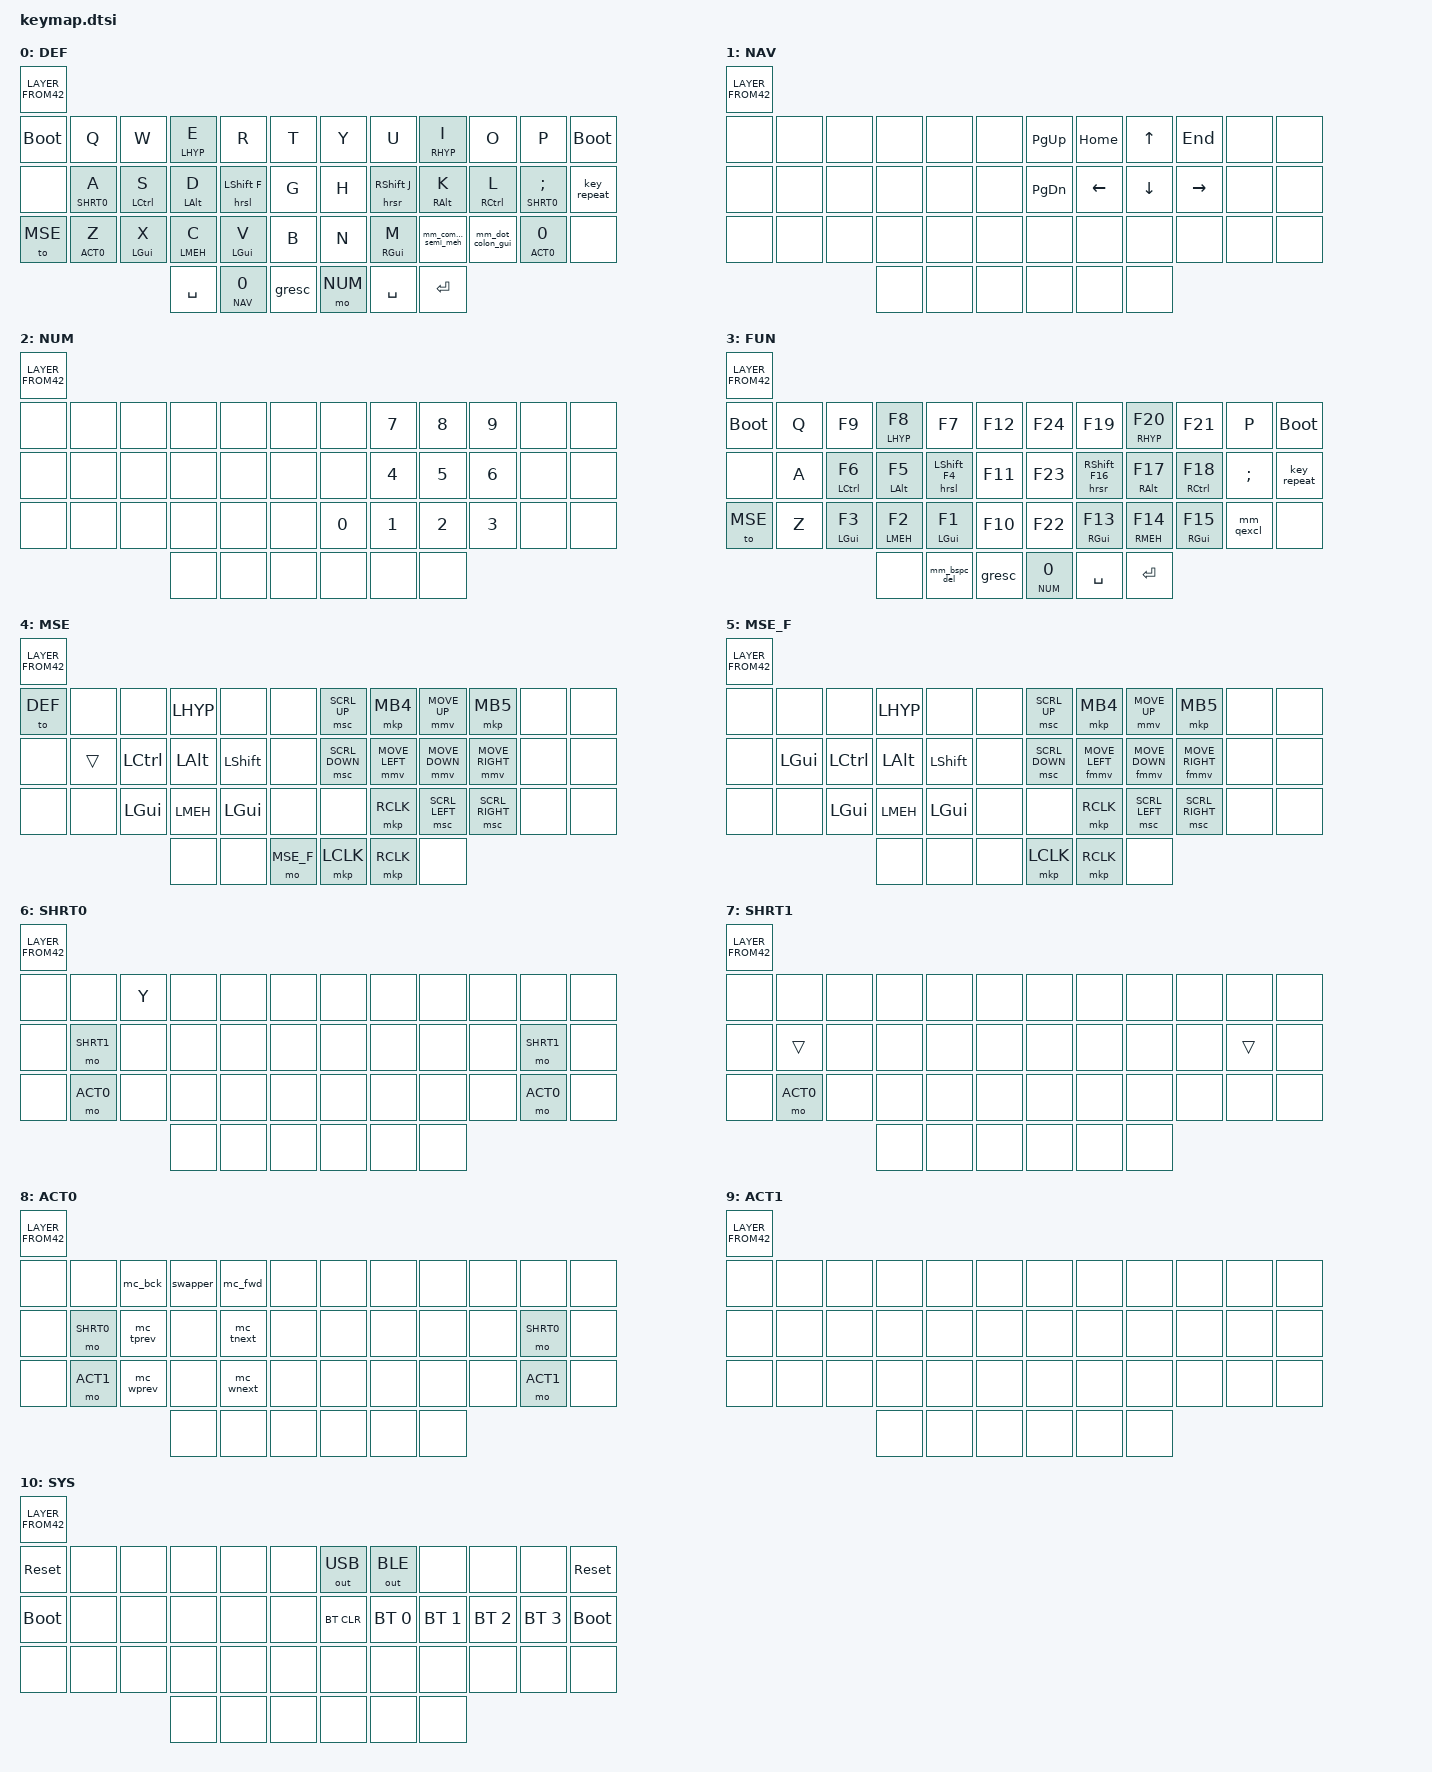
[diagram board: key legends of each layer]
/*
 * Copyright (c) 2020 The ZMK Contributors
 *
 * SPDX-License-Identifier: MIT
 */

#include <dt-bindings/zmk/bt.h>
#include <dt-bindings/zmk/keys.h>
// #include <dt-bindings/zmk/mouse.h>
#include <dt-bindings/zmk/outputs.h>

#ifndef KEYMAP_DRAWER
#include "include/keys_de.h"
#endif

#define DEF    0
#define NAV    1
#define NUM    2
#define FUN    3
#define MSE    4
#define MSE_F  5
#define SHRT0  6
#define SHRT1  7
#define ACT0   8
#define ACT1   9


#include "include/keypos.h"
#include "keycodes.dtsi"
#include "behaviors.dtsi"
#include "combos.dtsi"
#include "macros.dtsi"
#include "mouse.dtsi"

/ {
    conditional_layers {
        compatible = "zmk,conditional-layers";

        tri_layer  {
            if-layers = <NAV NUM>;
            then-layer = <FUN>;
        };
    };

    keymap {
        compatible = "zmk,keymap";

        default {
            display-name = "DEF";
            bindings = <LAYER_FROM42( \
// ┌───────────────────┬───────────────────┬───────────────────┬───────────────────┬───────────────────┬───────────────────╥───────────────────┬───────────────────┬───────────────────┬───────────────────┬───────────────────┬───────────────────┐
    &bootloader,        &kp Q,              &kp W,              &hrml LHYP E,       &kp R,              &kp T,              &kp Y,              &kp U,              &hrmr RHYP I,              &kp O,              &kp P,       &bootloader,       \
    &none,              &ltb SHRT0 A,       &hrml LCTL S,       &hrml LALT D,       &hrsl LSHFT F,      &kp G,              &kp H,              &hrsr RSHFT J,      &hrmr RALT K,      &hrmr RCTRL L,       &lt SHRT0 SEMI,           &key_repeat,       \
    &to MSE,            &ltb ACT0 Z,        &hrml LGUI X,       &hrml LMEH C,       &hrml LGUI V,       &kp B,              &kp N,              &hrmr RGUI M,       &mm_comma_semi_meh,    &mm_dot_colon_gui, &lt_qexcl ACT0 0,             &none,             \
                                                                &kp SPACE,          &lt_del NAV 0,       &gresc,             &mo NUM,   &kp SPACE,          &kp RET          \
//                                                             └───────────────────┴───────────────────┴───────────────────╨───────────────────┴───────────────────┴───────────────────┘
            )>;
        };

        navigation {
            display-name = "NAV";
            bindings = <LAYER_FROM42( \
// ┌───────────────────┬───────────────────┬───────────────────┬───────────────────┬───────────────────┬───────────────────╥───────────────────┬───────────────────┬───────────────────┬───────────────────┬───────────────────┬───────────────────┐
    &none,              &none,              &none,              &none,              &none,              &none,              &kp PG_UP,          &kp HOME,           &kp UP,             &kp END,            &none,              &none,             \
    &none,              &none,              &none,              &none,              &none,              &none,              &kp PG_DN,          &kp LEFT,           &kp DOWN,           &kp RIGHT,          &none,              &none,             \
    &none,              &none,              &none,              &none,              &none,              &none,              &none,              &none,              &none,              &none,              &none,              &none,             \
                                                                &none,              &none,              &none,              &none,              &none,              &none            \
//                                                             └───────────────────┴───────────────────┴───────────────────╨───────────────────┴───────────────────┴───────────────────┘
            )>;
        };

        number {
            display-name = "NUM";
            bindings = <LAYER_FROM42( \
// ┌───────────────────┬───────────────────┬───────────────────┬───────────────────┬───────────────────┬───────────────────╥───────────────────┬───────────────────┬───────────────────┬───────────────────┬───────────────────┬───────────────────┐
    &none,              &none,              &none,              &none,              &none,              &none,              &none,              &kp N7,             &kp N8,             &kp N9,              &none,              &none,             \
    &none,              &none,              &none,              &none,              &none,              &none,              &none,              &kp N4,             &kp N5,             &kp N6,              &none,              &none,             \
    &none,              &none,              &none,              &none,              &none,              &none,              &kp N0,             &kp N1,             &kp N2,             &kp N3,              &none,              &none,             \
                                                                &none,              &none,              &none,              &none,              &none,              &none            \
//                                                             └───────────────────┴───────────────────┴───────────────────╨───────────────────┴───────────────────┴───────────────────┘
            )>;
        };

        function {
            display-name = "FUN";
            bindings = <LAYER_FROM42( \
// ┌───────────────────┬───────────────────┬───────────────────┬───────────────────┬───────────────────┬───────────────────╥───────────────────┬───────────────────┬───────────────────┬───────────────────┬───────────────────┬───────────────────┐
    &bootloader,        &kp Q,              &kp F9,             &hrml LHYP F8,      &kp F7,             &kp F12,            &kp F24,              &kp F19,            &hrmr RHYP F20,     &kp F21,              &kp P,       &bootloader,       \
    &none,              &kp A,              &hrml LCTL F6,      &hrml LALT F5,      &hrsl LSHFT F4,     &kp F11,            &kp F23,              &hrsr RSHFT F16,      &hrmr RALT F17,      &hrmr RCTRL F18,       &kp SEMI,           &key_repeat,       \
    &to MSE,            &kp Z,              &hrml LGUI F3,      &hrml LMEH F2,      &hrml LGUI F1,      &kp F10,            &kp F22,              &hrmr RGUI F13,     &hrmr RMEH F14,     &hrmr RGUI F15,     &mm_qexcl,             &none,             \
                                                                &none,              &mm_bspc_del,       &gresc,             &lt_e NUM 0,        &kp SPACE,          &kp RET          \
      //                                                       └───────────────────┴───────────────────┴───────────────────╨───────────────────┴───────────────────┴───────────────────┘
            )>;
        };
        mouse {
            display-name = "MSE";
            bindings = <LAYER_FROM42( \
// ┌───────────────────┬───────────────────┬───────────────────┬───────────────────┬───────────────────┬───────────────────╥───────────────────┬───────────────────┬───────────────────┬───────────────────┬───────────────────┬───────────────────┐
    &to DEF,            &none,              &none,              &kp LHYP,           &none,              &none,              &msc SCRL_UP,       &mkp MB4,           &mmv MOVE_UP,       &mkp MB5,           &none,              &none,             \
    &none,              &trans,             &kp LCTL,           &kp LALT,           &kp LSHFT,          &none,              &msc SCRL_DOWN,     &mmv MOVE_LEFT,     &mmv MOVE_DOWN,     &mmv MOVE_RIGHT,    &none,              &none,             \
    &none,              &none,              &kp LGUI,           &kp LMEH,           &kp LGUI,           &none,              &none,              &mkp RCLK,          &msc SCRL_LEFT,     &msc SCRL_RIGHT,    &none,              &none,             \
                                                                &none,              &none,              &mo MSE_F,          &mkp LCLK,          &mkp RCLK,          &none            \
//                                                             └───────────────────┴───────────────────┴───────────────────╨───────────────────┴───────────────────┴───────────────────┘
            )>;
        };

        mouse_fast {
            display-name = "MSE_F";
            bindings = <LAYER_FROM42( \
// ┌───────────────────┬───────────────────┬───────────────────┬───────────────────┬───────────────────┬───────────────────╥───────────────────┬───────────────────┬───────────────────┬───────────────────┬───────────────────┬───────────────────┐
    &none,              &none,              &none,              &kp LHYP,           &none,              &none,              &msc SCRL_UP,       &mkp MB4,           &mmv MOVE_UP,       &mkp MB5,           &none,              &none,             \
    &none,              &kp LGUI,           &kp LCTL,           &kp LALT,           &kp LSHFT,          &none,              &msc SCRL_DOWN,     &fmmv MOVE_LEFT,     &fmmv MOVE_DOWN,     &fmmv MOVE_RIGHT,    &none,              &none,             \
    &none,              &none,              &kp LGUI,           &kp LMEH,           &kp LGUI,              &none,              &none,              &mkp RCLK,          &msc SCRL_LEFT,     &msc SCRL_RIGHT,    &none,              &none,             \
                                                                &none,              &none,              &none,              &mkp LCLK,          &mkp RCLK,          &none            \
//                                                             └───────────────────┴───────────────────┴───────────────────╨───────────────────┴───────────────────┴───────────────────┘
            )>;
        };
        shortcuts0 {
            display-name = "SHRT0";
            bindings = <LAYER_FROM42( \
// ┌───────────────────┬───────────────────┬───────────────────┬───────────────────┬───────────────────┬───────────────────╥───────────────────┬───────────────────┬───────────────────┬───────────────────┬───────────────────┬───────────────────┐
    &none,              &none,              &kp Y,              &none,              &none,              &none,              &none,              &none,              &none,              &none,              &none,              &none,             \
    &none,              &mo SHRT1,          &none,              &none,              &none,              &none,              &none,              &none,              &none,              &none,              &mo SHRT1,              &none,             \
    &none,              &mo ACT0,              &none,              &none,              &none,              &none,              &none,              &none,              &none,              &none,              &mo ACT0,              &none,             \
                                                                &none,              &none,              &none,              &none,              &none,              &none            \
//                                                             └───────────────────┴───────────────────┴───────────────────╨───────────────────┴───────────────────┴───────────────────┘
            )>;
        };            
        shortcuts1 {
            display-name = "SHRT1";
            bindings = <LAYER_FROM42( \
// ┌───────────────────┬───────────────────┬───────────────────┬───────────────────┬───────────────────┬───────────────────╥───────────────────┬───────────────────┬───────────────────┬───────────────────┬───────────────────┬───────────────────┐
    &none,              &none,              &none,              &none,              &none,              &none,              &none,              &none,              &none,              &none,              &none,              &none,             \
    &none,              &trans,              &none,              &none,              &none,              &none,              &none,              &none,              &none,              &none,              &trans,              &none,             \
    &none,              &mo ACT0,              &none,              &none,              &none,              &none,              &none,              &none,              &none,              &none,              &none,              &none,             \
                                                                &none,              &none,              &none,              &none,              &none,              &none            \
//                                                             └───────────────────┴───────────────────┴───────────────────╨───────────────────┴───────────────────┴───────────────────┘
            )>;
        };

        actions0 {
            display-name = "ACT0";
            bindings = <LAYER_FROM42( \
// ┌───────────────────┬───────────────────┬───────────────────┬───────────────────┬───────────────────┬───────────────────╥───────────────────┬───────────────────┬───────────────────┬───────────────────┬───────────────────┬───────────────────┐
    &none,              &none,              &mc_bck,            &swapper,        &mc_fwd,              &none,              &none,              &none,              &none,              &none,              &none,              &none,             \
    &none,              &mo SHRT0,          &mc_tprev,          &none,              &mc_tnext,              &none,              &none,              &none,              &none,              &none,          &mo SHRT0,          &none,             \
    &none,              &mo ACT1,              &mc_wprev,       &none,           &mc_wnext,              &none,              &none,              &none,              &none,              &none,           &mo ACT1,           &none,             \
                                                                &none,              &none,              &none,              &none,              &none,              &none            \
//                                                             └───────────────────┴───────────────────┴───────────────────╨───────────────────┴───────────────────┴───────────────────┘
            )>;
        };            
        actions1 {
            display-name = "ACT1";
            bindings = <LAYER_FROM42( \
// ┌───────────────────┬───────────────────┬───────────────────┬───────────────────┬───────────────────┬───────────────────╥───────────────────┬───────────────────┬───────────────────┬───────────────────┬───────────────────┬───────────────────┐
    &none,              &none,              &none,              &none,              &none,              &none,              &none,              &none,              &none,              &none,              &none,              &none,             \
    &none,              &none,              &none,              &none,              &none,              &none,              &none,              &none,              &none,              &none,              &none,              &none,             \
    &none,              &none,              &none,              &none,              &none,              &none,              &none,              &none,              &none,              &none,              &none,              &none,             \
                                                                &none,              &none,              &none,              &none,              &none,              &none            \
//                                                             └───────────────────┴───────────────────┴───────────────────╨───────────────────┴───────────────────┴───────────────────┘
            )>;
        };
        system {
            display-name = "SYS";
            bindings = <LAYER_FROM42( \
// ┌───────────────────┬───────────────────┬───────────────────┬───────────────────┬───────────────────┬───────────────────╥───────────────────┬───────────────────┬───────────────────┬───────────────────┬───────────────────┬───────────────────┐
    &sys_reset,         &none,              &none,              &none,              &none,              &none,              &out OUT_USB,       &out OUT_BLE,       &none,              &none,              &none,              &sys_reset,        \
    &bootloader,        &none,              &none,              &none,              &none,              &none,              &bt BT_CLR,         &bt BT_SEL 0,       &bt BT_SEL 1,       &bt BT_SEL 2,       &bt BT_SEL 3,       &bootloader,       \
    &none,              &none,              &none,              &none,              &none,              &none,              &none,              &none,              &none,              &none,              &none,              &none,             \
                                                                &none,              &none,              &none,              &none,              &none,              &none            \
//                                                             └───────────────────┴───────────────────┴───────────────────╨───────────────────┴───────────────────┴───────────────────┘
            )>;
        };        
        extra1 {
            status = "reserved";
        };

        extra2 {
            status = "reserved";
        };
    };
};
